AUTOSAR XML
package /Chassis
  sender receiver interface WheelSpeedIf
    data WheelSpeedRpm
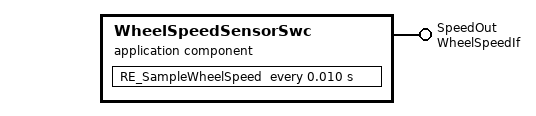
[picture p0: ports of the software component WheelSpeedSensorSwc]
  application sw component type WheelSpeedSensorSwc
    provide port SpeedOut: provided-interface=WheelSpeedIf
    behavior WheelSpeedSensor_IB
      runnable RE_SampleWheelSpeed: execution-time-wcet=0.0015
      timing event TE_10ms: start-on-event=RE_SampleWheelSpeed, period=0.010
